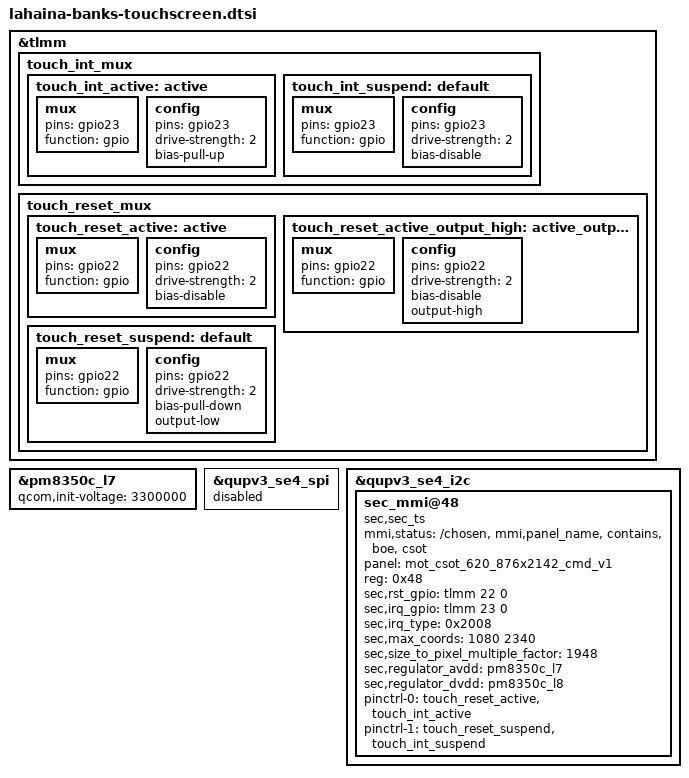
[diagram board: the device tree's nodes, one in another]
&tlmm {
	touch_int_mux {
		touch_int_active: active {
			mux {
				pins = "gpio23";
				function = "gpio";
			};
			config {
				pins = "gpio23";
				drive-strength = <2>;
				bias-pull-up;
			};
		};

		touch_int_suspend: default {
			mux {
				pins = "gpio23";
				function = "gpio";
			};
			config {
				pins = "gpio23";
				drive-strength = <2>;
				bias-disable;
			};
		};
	};

	touch_reset_mux {
		touch_reset_active: active {
			mux {
				pins = "gpio22";
				function = "gpio";
			};
			config {
				pins = "gpio22";
				drive-strength = <2>;
				bias-disable;
			};
		};

		touch_reset_active_output_high: active_output_high {
			mux {
				pins = "gpio22";
				function = "gpio";
			};
			config {
				pins = "gpio22";
				drive-strength = <2>;
				bias-disable;
				output-high;
			};
		};

		touch_reset_suspend: default {
			mux {
				pins = "gpio22";
				function = "gpio";
			};
			config {
				pins = "gpio22";
				drive-strength = <2>;
				bias-pull-down;
				output-low;
			};
		};
	};
};

&pm8350c_l7 {
	qcom,init-voltage = <3300000>;
};

&qupv3_se4_spi {
	status = "disabled";
};

&qupv3_se4_i2c {
	status = "ok";

	sec_mmi@48 {
		mmi,status = "/chosen","mmi,panel_name","contains","boe","csot";
		panel = <&mot_csot_620_876x2142_cmd_v1>;
		compatible = "sec,sec_ts";
		reg = <0x48>;
		sec,rst_gpio = <&tlmm 22 0>;
		sec,irq_gpio = <&tlmm 23 0>;
		sec,irq_type = <0x2008>; /*IRQF_TRIGGER_LOW | IRQF_ONESHOT*/
		sec,max_coords = <1080 2340>;
		sec,size_to_pixel_multiple_factor = <1948>;
		sec,regulator_avdd = "pm8350c_l7";
		sec,regulator_dvdd = "pm8350c_l8";
		pinctrl-names = "on_state", "off_state";
		pinctrl-0 = <&touch_reset_active &touch_int_active>;
		pinctrl-1 = <&touch_reset_suspend &touch_int_suspend>;
	};
};
